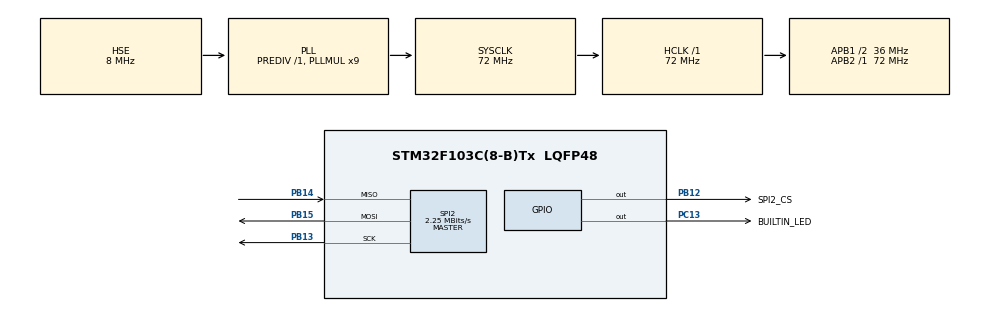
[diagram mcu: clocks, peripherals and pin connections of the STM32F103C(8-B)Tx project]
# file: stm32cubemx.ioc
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Dma.Request0=SPI2_RX
Dma.Request1=SPI2_TX
Dma.SPI2_RX.0.Direction=DMA_PERIPH_TO_MEMORY
Dma.SPI2_RX.0.Instance=DMA1_Channel4
Dma.SPI2_RX.0.MemDataAlignment=DMA_MDATAALIGN_BYTE
Dma.SPI2_RX.0.MemInc=DMA_MINC_ENABLE
Dma.SPI2_RX.0.Mode=DMA_NORMAL
Dma.SPI2_RX.0.PeriphDataAlignment=DMA_PDATAALIGN_BYTE
Dma.SPI2_RX.0.PeriphInc=DMA_PINC_DISABLE
Dma.SPI2_RX.0.Priority=DMA_PRIORITY_MEDIUM
Dma.SPI2_TX.1.Direction=DMA_MEMORY_TO_PERIPH
Dma.SPI2_TX.1.Instance=DMA1_Channel5
Dma.SPI2_TX.1.MemDataAlignment=DMA_MDATAALIGN_BYTE
Dma.SPI2_TX.1.MemInc=DMA_MINC_ENABLE
Dma.SPI2_TX.1.Mode=DMA_NORMAL
Dma.SPI2_TX.1.PeriphDataAlignment=DMA_PDATAALIGN_BYTE
Dma.SPI2_TX.1.PeriphInc=DMA_PINC_DISABLE
Dma.SPI2_TX.1.Priority=DMA_PRIORITY_MEDIUM
Mcu.Family=STM32F1
Mcu.Name=STM32F103C(8-B)Tx
Mcu.Package=LQFP48
NVIC.DMA1_Channel4_IRQn=true\:0\:0\:false\:false\:true\:false\:true
NVIC.DMA1_Channel5_IRQn=true\:0\:0\:false\:false\:true\:false\:true
NVIC.PriorityGroup=NVIC_PRIORITYGROUP_4
PA13.Mode=Serial_Wire
PA13.Signal=SYS_JTMS-SWDIO
PA14.Mode=Serial_Wire
PA14.Signal=SYS_JTCK-SWCLK
PB12.GPIO_Label=SPI2_CS
PB12.PinState=GPIO_PIN_SET
PB12.Signal=GPIO_Output
PB13.Mode=Full_Duplex_Master
PB13.Signal=SPI2_SCK
PB14.Mode=Full_Duplex_Master
PB14.Signal=SPI2_MISO
PB15.Mode=Full_Duplex_Master
PB15.Signal=SPI2_MOSI
PC13-TAMPER-RTC.GPIO_Label=BUILTIN_LED
PC13-TAMPER-RTC.GPIO_ModeDefaultOutputPP=GPIO_MODE_OUTPUT_OD
PC13-TAMPER-RTC.PinState=GPIO_PIN_SET
PC13-TAMPER-RTC.Signal=GPIO_Output
PC14-OSC32_IN.Mode=LSE-External-Oscillator
PC14-OSC32_IN.Signal=RCC_OSC32_IN
PC15-OSC32_OUT.Mode=LSE-External-Oscillator
PC15-OSC32_OUT.Signal=RCC_OSC32_OUT
PD0-OSC_IN.Mode=HSE-External-Oscillator
PD0-OSC_IN.Signal=RCC_OSC_IN
PD1-OSC_OUT.Mode=HSE-External-Oscillator
PD1-OSC_OUT.Signal=RCC_OSC_OUT
ProjectManager.HeapSize=0x200
ProjectManager.StackSize=0x400
ProjectManager.TargetToolchain=Makefile
RCC.AHBFreq_Value=72000000
RCC.APB1CLKDivider=RCC_HCLK_DIV2
RCC.APB1Freq_Value=36000000
RCC.APB1TimFreq_Value=72000000
RCC.APB2Freq_Value=72000000
RCC.APB2TimFreq_Value=72000000
RCC.HCLKFreq_Value=72000000
RCC.PLLMUL=RCC_PLL_MUL9
RCC.PLLSourceVirtual=RCC_PLLSOURCE_HSE
RCC.RTCClockSelection=RCC_RTCCLKSOURCE_LSE
RCC.SYSCLKFreq_VALUE=72000000
RCC.SYSCLKSource=RCC_SYSCLKSOURCE_PLLCLK
RCC.USBFreq_Value=48000000
RCC.USBPrescaler=RCC_USBCLKSOURCE_PLL_DIV1_5
SPI2.BaudRatePrescaler=SPI_BAUDRATEPRESCALER_16
SPI2.CalculateBaudRate=2.25 MBits/s
SPI2.Direction=SPI_DIRECTION_2LINES
SPI2.Mode=SPI_MODE_MASTER
SPI2.VirtualType=VM_MASTER
VP_RTC_VS_RTC_Activate.Mode=RTC_Enabled
board=custom

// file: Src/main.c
/* USER CODE BEGIN Header */
/**
  ******************************************************************************
  * @file           : main.c
  * @brief          : Main program body
  ******************************************************************************
  * @attention
  *
  * <h2><center>&copy; Copyright (c) 2021 STMicroelectronics.
  * All rights reserved.</center></h2>
  *
  * This software component is licensed by ST under BSD 3-Clause license,
  * the "License"; You may not use this file except in compliance with the
  * License. You may obtain a copy of the License at:
  *                        opensource.org/licenses/BSD-3-Clause
  *
  ******************************************************************************
  */
/* USER CODE END Header */
#include "main.h"
#include "dma.h"
#include "rtc.h"
#include "spi.h"
#include "gpio.h"

/* USER CODE BEGIN PV */
volatile uint8_t spi_ready = 0;
/* USER CODE END PV */

void SystemClock_Config(void);

int main(void)
{
  /* USER CODE BEGIN 1 */
  uint8_t tx_buffer[8];
  uint8_t rx_buffer[8];
  uint16_t result = 0;
  uint32_t time = 0;
  /* USER CODE END 1 */

  /* MCU Configuration--------------------------------------------------------*/

  /* Reset of all peripherals, Initializes the Flash interface and the Systick. */
  HAL_Init();

  /* Configure the system clock */
  SystemClock_Config();

  /* Initialize all configured peripherals */
  MX_GPIO_Init();
  MX_DMA_Init();
  MX_RTC_Init();
  MX_SPI2_Init();
  /* USER CODE BEGIN 2 */
  time = HAL_GetTick();
  /* USER CODE END 2 */

  /* Infinite loop */
  while (1)
  {
    if (HAL_GetTick() - time > 500)
    {
      time = HAL_GetTick();
      tx_buffer[0] = 0x01;
      tx_buffer[1] = 0xf0;
      tx_buffer[2] = 0x00;
      HAL_GPIO_WritePin(SPI2_CS_GPIO_Port, SPI2_CS_Pin, GPIO_PIN_RESET);
      HAL_SPI_TransmitReceive_DMA(&hspi2, tx_buffer, rx_buffer, 3);
    }
    if (spi_ready != 0)
    // if (hspi2.State == HAL_SPI_STATE_READY)
    {
      spi_ready = 0;
      result = ((uint16_t)rx_buffer[1] & 0x03) << 8;
      result |= rx_buffer[2];
      if (result < 512)
      {
        HAL_GPIO_WritePin(BUILTIN_LED_GPIO_Port, BUILTIN_LED_Pin, GPIO_PIN_SET);
      }
      else
      {
        HAL_GPIO_WritePin(BUILTIN_LED_GPIO_Port, BUILTIN_LED_Pin, GPIO_PIN_RESET);
      }
    }
  }
}

void SystemClock_Config(void)
{
  RCC_OscInitTypeDef RCC_OscInitStruct = {0};
  RCC_ClkInitTypeDef RCC_ClkInitStruct = {0};
  RCC_PeriphCLKInitTypeDef PeriphClkInit = {0};

  /** Initializes the RCC Oscillators according to the specified parameters
  * in the RCC_OscInitTypeDef structure.
  */
  RCC_OscInitStruct.OscillatorType = RCC_OSCILLATORTYPE_HSE|RCC_OSCILLATORTYPE_LSE;
  RCC_OscInitStruct.HSEState = RCC_HSE_ON;
  RCC_OscInitStruct.HSEPredivValue = RCC_HSE_PREDIV_DIV1;
  RCC_OscInitStruct.LSEState = RCC_LSE_ON;
  RCC_OscInitStruct.HSIState = RCC_HSI_ON;
  RCC_OscInitStruct.PLL.PLLState = RCC_PLL_ON;
  RCC_OscInitStruct.PLL.PLLSource = RCC_PLLSOURCE_HSE;
  RCC_OscInitStruct.PLL.PLLMUL = RCC_PLL_MUL9;
  if (HAL_RCC_OscConfig(&RCC_OscInitStruct) != HAL_OK)
  {
    Error_Handler();
  }
  /** Initializes the CPU, AHB and APB buses clocks
  */
  RCC_ClkInitStruct.ClockType = RCC_CLOCKTYPE_HCLK|RCC_CLOCKTYPE_SYSCLK
                              |RCC_CLOCKTYPE_PCLK1|RCC_CLOCKTYPE_PCLK2;
  RCC_ClkInitStruct.SYSCLKSource = RCC_SYSCLKSOURCE_PLLCLK;
  RCC_ClkInitStruct.AHBCLKDivider = RCC_SYSCLK_DIV1;
  RCC_ClkInitStruct.APB1CLKDivider = RCC_HCLK_DIV2;
  RCC_ClkInitStruct.APB2CLKDivider = RCC_HCLK_DIV1;

  if (HAL_RCC_ClockConfig(&RCC_ClkInitStruct, FLASH_LATENCY_2) != HAL_OK)
  {
    Error_Handler();
  }
  PeriphClkInit.PeriphClockSelection = RCC_PERIPHCLK_RTC;
  PeriphClkInit.RTCClockSelection = RCC_RTCCLKSOURCE_LSE;
  if (HAL_RCCEx_PeriphCLKConfig(&PeriphClkInit) != HAL_OK)
  {
    Error_Handler();
  }
}

/* USER CODE BEGIN 4 */
void HAL_SPI_TxRxCpltCallback(SPI_HandleTypeDef *hspi)
{
  HAL_GPIO_WritePin(SPI2_CS_GPIO_Port, SPI2_CS_Pin, GPIO_PIN_SET);
  spi_ready = 1;
}
/* USER CODE END 4 */

void Error_Handler(void)
{
  __disable_irq();
  while (1)
  {
  }
}

/************************ (C) COPYRIGHT STMicroelectronics *****END OF FILE****/
